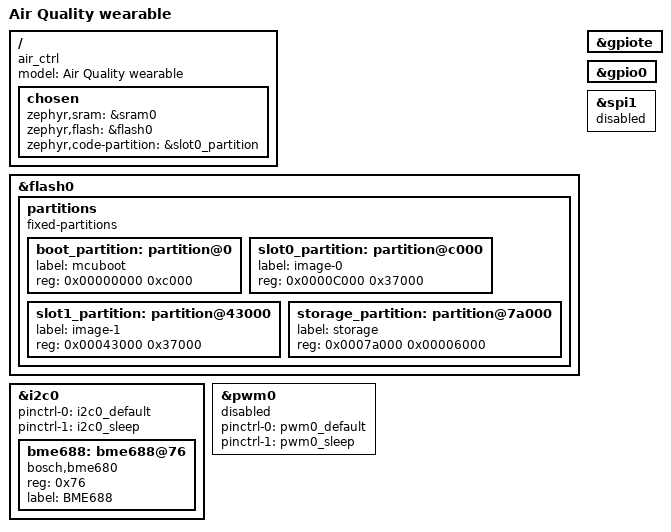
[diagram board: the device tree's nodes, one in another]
/dts-v1/;
#include <nordic/nrf52832_qfaa.dtsi>
#include "air_ctrl-pinctrl.dtsi"

/ {
	model = "Air Quality wearable";
	compatible = "air_ctrl";

	chosen {
		zephyr,sram = &sram0;
		zephyr,flash = &flash0;
		zephyr,code-partition = &slot0_partition;
	};
};

&flash0 {
	partitions {
		compatible = "fixed-partitions";
		#address-cells = <1>;
		#size-cells = <1>;

		boot_partition: partition@0 {
			label = "mcuboot";
			reg = <0x00000000 0xc000>;
		};

		slot0_partition: partition@c000 {
			label = "image-0";
			reg = <0x0000C000 0x37000>;
		};

		slot1_partition: partition@43000 {
			label = "image-1";
			reg = <0x00043000 0x37000>;
		};

		storage_partition: partition@7a000 {
			label = "storage";
			reg = <0x0007a000 0x00006000>;
		};
	};
};

&gpiote {
    status = "okay";
};

&gpio0 {
    status = "okay";
};

&i2c0 {
	status = "okay";
	pinctrl-0 = <&i2c0_default>;
	pinctrl-1 = <&i2c0_sleep>;
	pinctrl-names = "default", "sleep";

	bme688: bme688@76 {
		compatible = "bosch,bme680";
		reg = <0x76>;
		label = "BME688";
	};
};

&spi1 {
	status = "disabled";
};

&pwm0 {
	/* DISABLED: Pin conflict with backlight GPIO on P0.10 */
	status = "disabled";
	pinctrl-0 = <&pwm0_default>;
	pinctrl-1 = <&pwm0_sleep>;
	pinctrl-names = "default", "sleep";
};
